AUTOSAR XML (schema 4-2-2)
package /ASW_NVM/NVM/ImplementationDataTypes
  impl type Impl_NVM_DstPtrType_1024: category=ARRAY
    element ArrayElement: array-size=1024, array-size-semantics=FIXED-SIZE, implementation-data-type=uint8
package /ASW_NVM/ASW_NVM
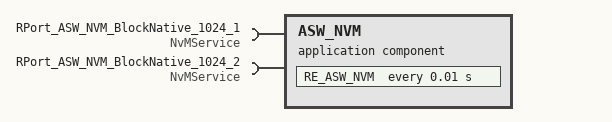
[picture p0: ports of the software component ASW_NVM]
  application sw component type ASW_NVM
    require port RPort_ASW_NVM_BlockNative_1024_1: required-interface=NvMService
    require port RPort_ASW_NVM_BlockNative_1024_2: required-interface=NvMService
    behavior IB_ASW_NVM: data-type-mapping=AppMode_Mapping
      timing event TE_ASW_NVM_10ms: start-on-event=RE_ASW_NVM, period=0.01
      per instance memory ASW_NVM_BlockNative_1024_1: implementation-data-type=Impl_NVM_DstPtrType_1024, type=ASW_NVM_BlockNative_1024_Type, type-definition=Impl_NVM_DstPtrType_1024
      per instance memory ASW_NVM_BlockNative_1024_2: implementation-data-type=Impl_NVM_DstPtrType_1024, type=ASW_NVM_BlockRedundant_1024_Type, type-definition=Impl_NVM_DstPtrType_1024
      runnable RE_ASW_NVM: symbol=RE_ASW_NVM_func
        18 x sync call:
          SynchronousServerCallPoint_0: operation=RPort_ASW_NVM_BlockNative_1024_1.EraseBlock
          SynchronousServerCallPoint_1: operation=RPort_ASW_NVM_BlockNative_1024_1.GetDataIndex
          SynchronousServerCallPoint_2: operation=RPort_ASW_NVM_BlockNative_1024_1.GetErrorStatus
          SynchronousServerCallPoint_3: operation=RPort_ASW_NVM_BlockNative_1024_1.InvalidateNvBlock
          SynchronousServerCallPoint_4: operation=RPort_ASW_NVM_BlockNative_1024_1.ReadBlock
          SynchronousServerCallPoint_5: operation=RPort_ASW_NVM_BlockNative_1024_1.RestoreBlockDefaults
          SynchronousServerCallPoint_6: operation=RPort_ASW_NVM_BlockNative_1024_1.SetDataIndex
          SynchronousServerCallPoint_7: operation=RPort_ASW_NVM_BlockNative_1024_1.SetRamBlockStatus
          SynchronousServerCallPoint_8: operation=RPort_ASW_NVM_BlockNative_1024_1.WriteBlock
          SynchronousServerCallPoint_9: operation=RPort_ASW_NVM_BlockNative_1024_2.EraseBlock
          SynchronousServerCallPoint_10: operation=RPort_ASW_NVM_BlockNative_1024_2.GetDataIndex
          SynchronousServerCallPoint_11: operation=RPort_ASW_NVM_BlockNative_1024_2.GetErrorStatus
          SynchronousServerCallPoint_12: operation=RPort_ASW_NVM_BlockNative_1024_2.InvalidateNvBlock
          SynchronousServerCallPoint_13: operation=RPort_ASW_NVM_BlockNative_1024_2.ReadBlock
          SynchronousServerCallPoint_14: operation=RPort_ASW_NVM_BlockNative_1024_2.RestoreBlockDefaults
          SynchronousServerCallPoint_15: operation=RPort_ASW_NVM_BlockNative_1024_2.SetDataIndex
          SynchronousServerCallPoint_16: operation=RPort_ASW_NVM_BlockNative_1024_2.SetRamBlockStatus
          SynchronousServerCallPoint_17: operation=RPort_ASW_NVM_BlockNative_1024_2.WriteBlock
      swc service dependency SwcServiceDependency
        assigned-datas:
          role=ramBlock, used-pim=ASW_NVM_BlockNative_1024_1
          role=ramBlock, used-pim=ASW_NVM_BlockNative_1024_2
        assigned-ports:
          port-prototype=RPort_ASW_NVM_BlockNative_1024_1, role=NvMService
          port-prototype=RPort_ASW_NVM_BlockNative_1024_2, role=NvMService
        service-needs:
          nv block needs NvBlockNeeds_NvM: category=READ, calc-ram-block-crc=false, check-static-block-id=false, n-rom-blocks=0, readonly=false, restore-at-start=true, store-at-shutdown=false, store-cyclic=false, store-immediate=true, write-only-once=false
